# STM32H73x register map
File version: 1.3
CPU: CM7 r0p1, little endian, MPU, FPU, 4 interrupt priority bits
Registers are 32-bit, read-write, reset 0x0 unless marked. A register's access mark holds for its fields unless they carry their own. Offsets are from the block's base; [hi:lo] are bit positions; {n}, {i} and the like mark numbered series; 'fields as' and 'values as' point back to an identical list.

## MPU — Memory protection unit
Base 0xE000ED90
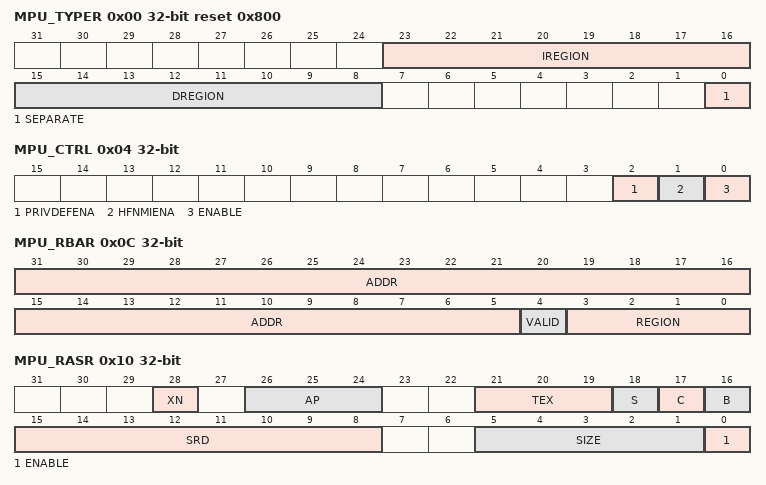
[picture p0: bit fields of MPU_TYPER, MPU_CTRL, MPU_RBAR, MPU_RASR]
0x00 MPU_TYPER ro reset 0x800 — MPU type register
  [23:16] IREGION — Number of MPU instruction regions
  [15:8] DREGION — Number of MPU data regions
  [0] SEPARATE — Separate flag
0x04 MPU_CTRL — MPU control register
  [2] PRIVDEFENA — Enable priviliged software access to default memory map
  [1] HFNMIENA — Enables the operation of MPU during hard fault
  [0] ENABLE — Enables the MPU
0x08 MPU_RNR — MPU region number register
  [7:0] REGION — MPU region
0x0C MPU_RBAR — MPU region base address register
  [31:5] ADDR — Region base address field
  [4] VALID — MPU region number valid
  [3:0] REGION — MPU region field
0x10 MPU_RASR — MPU region attribute and size register
  [28] XN — Instruction access disable bit
  [26:24] AP — Access permission
  [21:19] TEX — memory attribute
  [18] S — Shareable memory attribute
  [17] C — memory attribute
  [16] B — memory attribute
  [15:8] SRD — Subregion disable bits
  [5:1] SIZE — Size of the MPU protection region
  [0] ENABLE — Region enable bit.

## NVIC — Nested Vectored Interrupt Controller
Base 0xE000E100
{0x0+4i} ISER{i} (i=0..2) — Interrupt Set-Enable Register
  [31:0] SETENA
0x0C ISER3 — Interrupt Set-Enable Register
{0x80+4i} ICER{i} (i=0..2) — Interrupt Clear-Enable Register
  [31:0] CLRENA
0x8C ICER3 — Interrupt Clear-Enable Register
{0x100+4i} ISPR{i} (i=0..2) — Interrupt Set-Pending Register
  [31:0] SETPEND
0x10C ISPR3 — Interrupt Set-Pending Register
{0x180+4i} ICPR{i} (i=0..2) — Interrupt Clear-Pending Register
  [31:0] CLRPEND
0x1C0 ICPR3 — Interrupt Clear-Pending Register
{0x200+4i} IABR{i} ro (i=0..2) — Interrupt Active Bit Register
  [31:0] ACTIVE
0x20C IABR3 — Interrupt Active Bit Register
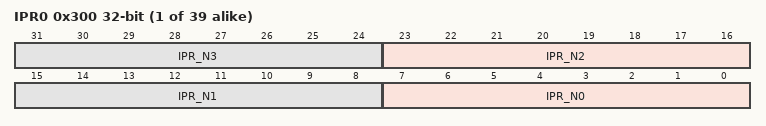
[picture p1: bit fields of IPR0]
{0x300+4i} IPR{i} (i=0..38) — Interrupt Priority Register
  [8n+7:8n] IPR_N{n} (n=0..3)

## NVIC_STIR — Nested vectored interrupt controller
Base 0xE000EF00
0x00 STIR — Software trigger interrupt register
  [8:0] INTID — Software generated interrupt ID

## OPAMP — Operational amplifiers
Base 0x40009000
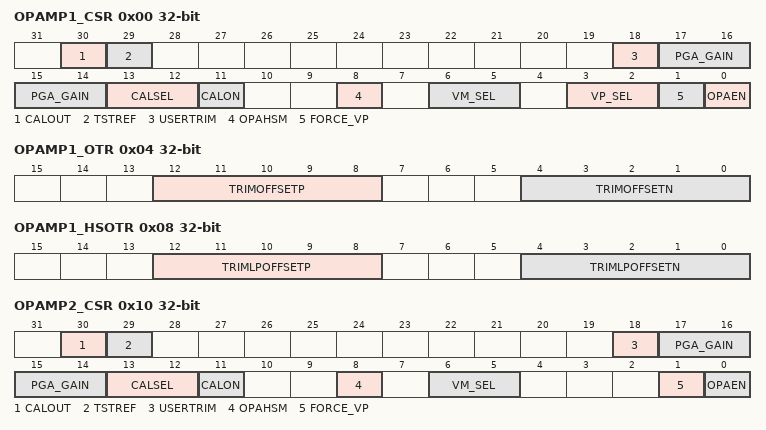
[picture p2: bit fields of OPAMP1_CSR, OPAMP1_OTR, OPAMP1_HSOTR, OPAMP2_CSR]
0x00 OPAMP1_CSR — OPAMP1 control/status register
  [30] CALOUT — Operational amplifier calibration output
  [29] TSTREF — OPAMP calibration reference voltage output control (reserved for test)
  [18] USERTRIM — User trimming enable
  [17:14] PGA_GAIN — allows to switch from AOP offset trimmed values to AOP offset
  [13:12] CALSEL — Calibration selection
  [11] CALON — Calibration mode enabled
  [8] OPAHSM — Operational amplifier high-speed mode
  [6:5] VM_SEL — Inverting input selection
  [3:2] VP_SEL — Operational amplifier PGA mode
  [1] FORCE_VP — Force internal reference on VP (reserved for test
  [0] OPAEN — Operational amplifier Enable
0x04 OPAMP1_OTR — OPAMP1 offset trimming register in normal mode
  [12:8] TRIMOFFSETP — Trim for PMOS differential pairs
  [4:0] TRIMOFFSETN — Trim for NMOS differential pairs
0x08 OPAMP1_HSOTR — OPAMP1 offset trimming register in low-power mode
  [12:8] TRIMLPOFFSETP — Trim for PMOS differential pairs
  [4:0] TRIMLPOFFSETN — Trim for NMOS differential pairs
0x10 OPAMP2_CSR — OPAMP2 control/status register
  [30] CALOUT — Operational amplifier calibration output
  [29] TSTREF — OPAMP calibration reference voltage output control (reserved for test)
  [18] USERTRIM — User trimming enable
  [17:14] PGA_GAIN — Operational amplifier Programmable amplifier gain value
  [13:12] CALSEL — Calibration selection
  [11] CALON — Calibration mode enabled
  [8] OPAHSM — Operational amplifier high-speed mode
  [6:5] VM_SEL — Inverting input selection
  [1] FORCE_VP — Force internal reference on VP (reserved for test)
  [0] OPAEN — Operational amplifier Enable
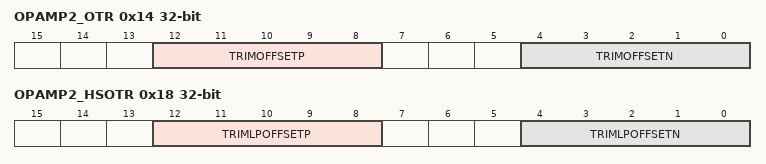
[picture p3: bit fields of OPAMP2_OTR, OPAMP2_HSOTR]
0x14 OPAMP2_OTR — OPAMP2 offset trimming register in normal mode
  fields as OPAMP1_OTR
0x18 OPAMP2_HSOTR — OPAMP2 offset trimming register in low-power mode
  fields as OPAMP1_HSOTR
